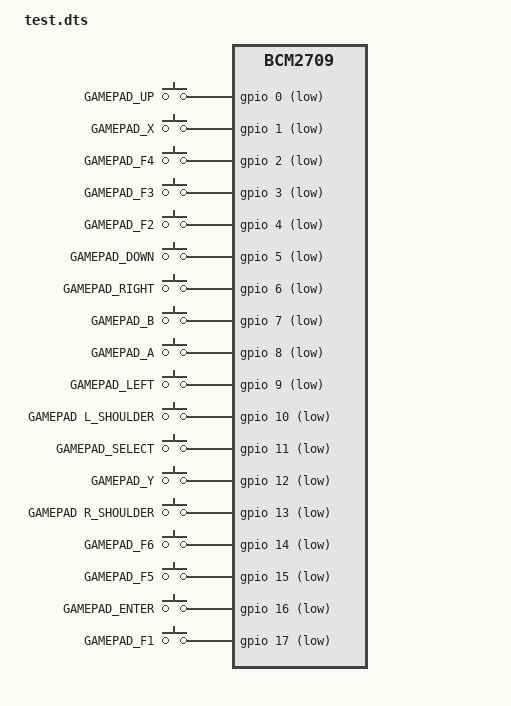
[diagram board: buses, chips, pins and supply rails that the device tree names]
    /dts-v1/;
    /plugin/;
    / {
       compatible = "brcm,bcm2835", "brcm,bcm2708", "brcm,bcm2709";
       
       fragment@0 {
          target-path = "/";
          __overlay__ {
             keypad: gamepad {
                compatible = "gpio-keys";
                #address-cells = <1>;
                #size-cells = <0>;
		autorepeat;
                up {
                   label = "GAMEPAD_UP";
                   linux,code = <103>;
                   gpios = <&gpio 0 1>;
                };
                x {
                   label = "GAMEPAD_X";
                   linux,code = <45>;
                   gpios = <&gpio 1 1>;
                 };
                4 {
                   label = "GAMEPAD_F4";
                   linux,code = <5>;
                   gpios = <&gpio 2 1>;
                };
                3 {
                   label = "GAMEPAD_F3";
                   linux,code = <4>;
                   gpios = <&gpio 3 1>;
                };	
                2 {
                   label = "GAMEPAD_F2";
                   linux,code = <3>;
                   gpios = <&gpio 4 1>;
                };
                down {
                   label = "GAMEPAD_DOWN";
                   linux,code = <108>;
                   gpios = <&gpio 5 1>;
                };
                right {
                   label = "GAMEPAD_RIGHT";
                   linux,code = <106>;
                   gpios = <&gpio 6 1>;
                };
                b {
                   label = "GAMEPAD_B";
                   linux,code = <48>;
                   gpios = <&gpio 7 1>;
                };
                a {
                   label = "GAMEPAD_A";
                   linux,code = <30>;
                   gpios = <&gpio 8 1>;
                };
                left {
                   label = "GAMEPAD_LEFT";
                   linux,code = <105>;
                   gpios = <&gpio 9 1>;
                };
                q {
                   label = "GAMEPAD L_SHOULDER";
                   linux,code = <16>;
                   gpios = <&gpio 10 1>;
                };
                backspace {
                   label = "GAMEPAD_SELECT";
                   linux,code = <14>;
                   gpios = <&gpio 11 1>;
                };
                y {
                   label = "GAMEPAD_Y";
                   linux,code = <21>;
                   gpios = <&gpio 12 1>;
                };
                w {
                   label = "GAMEPAD R_SHOULDER";
                   linux,code = <17>;
                   gpios = <&gpio 13 1>;
                };
                6 {
                   label = "GAMEPAD_F6";
                   linux,code = <7>;
                   gpios = <&gpio 14 1>;
                };
                5 {
                   label = "GAMEPAD_F5";
                   linux,code = <6>;
                   gpios = <&gpio 15 1>;
                };
                enter {
                   label = "GAMEPAD_ENTER";
                   linux,code = <28>;
                   gpios = <&gpio 16 1>;
                };
                1 {
                   label = "GAMEPAD_F1";
                   linux,code = <2>;
                   gpios = <&gpio 17 1>;
                };
             };
          };
       };
    };
